# W7500x register map
Vendor: WIZnet; File version: 1.0.0
CPU: CM0 r0p0, little endian, no MPU, no FPU, 2 interrupt priority bits
Registers are 32-bit, read-write, reset 0x0 unless marked. A register's access mark holds for its fields unless they carry their own. Offsets are from the block's base; [hi:lo] are bit positions; {n}, {i} and the like mark numbered series; 'fields as' and 'values as' point back to an identical list.

## CRG
Base 0x41001000
0x00 OSC_PDR — Oscillator power down register
  [0] OSCPD — Internal 8MHz RC oscillator power down flag
    0=Normal; 1=PowerDown
0x10 PLL_PDR reset 0x1 — PLL power down register
  [0] PLLPD — PLL power down flag
    0=PowerDown; 1=Normal
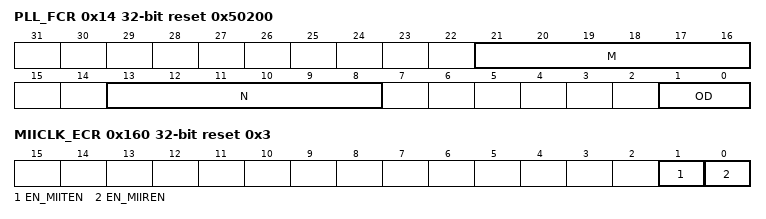
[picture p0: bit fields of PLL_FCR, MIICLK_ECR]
0x14 PLL_FCR reset 0x50200 — PLL frequency calculating register
  [21:16] M — Loop divider control bits
  [13:8] N — Pre divider control bits
  [1:0] OD — Output divider control bits
0x18 PLL_OER reset 0x1 — PLL output enable register
  [0] PLLOEN — PLL output flag
    0=Disable (VCO is working but FOUT is low only); 1=Enable
0x1C PLL_BPR — PLL bypass register
  [0] PLLBP — PLL bypass flag
0x20 PLL_IFSR — PLL input frequency select register
  [0] PLLIS — PLL input clock source select flag
    0=Internal 8MHz RC oscillator clock (RCLK); 1=External oscillator clock (OCLK, 8MHz-24MHz)
0x30 FCLK_SSR reset 0x1 — FCLK source select register
  [1:0] FCKSRC — FCLK source select bits
    other=PLL (Output clock of PLL (MCLK)); 2=Internal 8MHz RC oscillator clock (RCLK); 3=External oscillator clock (OCLK, 8MHz-24MHz)
0x34 FCLK_PVSR — FCLK prescale value select register
  [1:0] FCKPRE — FCLK prescale value select bits
    0=Bypass (1/1); 1=Half (1/2); 2=By4 (1/4); 3=By8 (1/8)
0x40 SSPCLK_SSR reset 0x1 — SSPCLK source select register
  [1:0] SSPCSS — SSPCLK source select bits
    0=Disable; 1=PLL (Output clock of PLL (MCLK)); 2=Internal 8MHz RC oscillator clock (RCLK); 3=External oscillator clock (OCLK, 8MHz-24MHz)
0x44 SSPCLK_PVSR — SSPCLK prescale value select register
  [1:0] SSPCP — SSPCLK prescale value select bits
    0=Bypass (1/1); 1=Half (1/2); 2=By4 (1/4); 3=By8 (1/8)
0x60 ADCCLK_SSR reset 0x1 — ADCCLK source select register
  [1:0] ADCSS — ADCCLK source select bits
    values as SSPCLK_SSR.SSPCSS
0x64 ADCCLK_PVSR — ADCCLK prescale value select register
  [1:0] ADCCP — ADCCLK prescale value select bits
    0=Bypass (1/1); 1=Half (1/2); 2=By4 (1/4); 3=By8 (1/8)
0x70 TIMER0CLK_SSR reset 0x1 — TIMER0CLK source select register
  [1:0] TCSS — TIMERnCLK source select bits
    values as SSPCLK_SSR.SSPCSS
0x74 TIMER0CLK_PVSR — TIMER0CLK prescale value select register
  [2:0] TCPS — TIMERnCLK prescale value select bits
    0=Bypass (1/1); 1=Half (1/2); 2=By4 (1/4); 3=By8 (1/8); 4=By16 (1/16); 5=By32 (1/32); 6=By64 (1/64); 7=By128 (1/128)
0x80 TIMER1CLK_SSR reset 0x1 — TIMER1CLK source select register
  fields as TIMER0CLK_SSR
0x84 TIMER1CLK_PVSR — TIMER1CLK prescale value select register
  fields as TIMER0CLK_PVSR
{0xB0+0x10*i} PWM{i}CLK_SSR reset 0x1 (i=0..7) — PWM{i}CLK source select register
  [1:0] PCSS — PWMnCLK source select bits
    values as SSPCLK_SSR.SSPCSS
{0xB4+0x10*i} PWM{i}CLK_PVSR (i=0..7) — PWM{i}CLK prescale value select register
  [2:0] PCPS — PWMnCLK prescale value select bits
    values as TIMER0CLK_PVSR.TCPS
0x130 RTC_HS_SSR reset 0x1 — RTCCLK source select register
  [1:0] RTCHS — RTC High Speed source select bits
    values as SSPCLK_SSR.SSPCSS
0x134 RTC_HS_PVSR — RTCCLK prescale value select register
  [2:0] RTCPRE — RTC High Speed prescale value select bits
    values as TIMER0CLK_PVSR.TCPS
0x13C RTC_SSR — RTCCLK 32K select register
  [0] RTCSEL — RTC source select bits
    0=RTCCLK_hs; 1=32K_OSC_CLK (Low speed external oscillator clock)
0x140 WDOGCLK_HS_SSR reset 0x1 — WDOGCLK High Speed source select register
  [1:0] WDHS — WDOGCLK High Speed source select bits
    values as SSPCLK_SSR.SSPCSS
0x144 WDOGCLK_HS_PVSR — WDOGCLK High Speed prescale value select register
  [2:0] WDPRE — WDOGCLK High Speed prescale value select bits
    values as TIMER0CLK_PVSR.TCPS
0x150 UARTCLK_SSR reset 0x1 — UARTCLK source select register
  [1:0] UCSS — UARTCLK source select bits
    values as SSPCLK_SSR.SSPCSS
0x154 UARTCLK_PVSR — UARTCLK prescale value select register
  [1:0] UCP — UARTCLK prescale value select bits
    0=Bypass (1/1); 1=Half (1/2); 2=By4 (1/4); 3=By8 (1/8)
0x160 MIICLK_ECR reset 0x3 — MII clock enable control register
  [1] EN_MIITEN — MII TX Clock source enable flag
  [0] EN_MIIREN — MII RX Clock source enable register flag
0x170 MONCLK_SSR — Select clock source for monitoring (monitoring pin : PA_02)
  [4:0] CLKMON_SEL — Monitoring Clock source select bits
    0=PLL (MCLK); 1=FCLK; 2=Internal 8MHz RC oscillator clock (RCLK); 3=External oscillator clock (OCLK, 8MHz-24MHz); 4=ADCCLK; 5=SSPCLK; 6=TIMCLK0; 7=TIMCLK1; {v}=PWMCLK{v-8} (v=8..15); 16=UARTCLK; 17=MII_RCK; 18=MII_TCK; 19=RTCCLK
